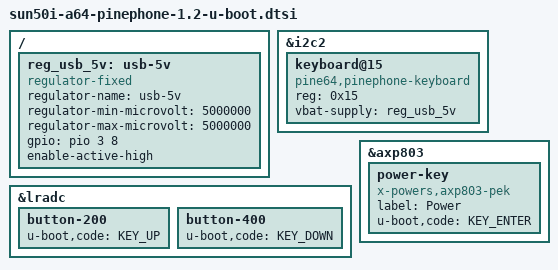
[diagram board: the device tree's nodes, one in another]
// SPDX-License-Identifier: (GPL-2.0+ OR MIT)
/*
 * U-Boot additions for the PinePhone: the three buttons act as a keyboard so
 * the boot menu can be driven without a serial console, and so does the
 * keyboard case when it is attached.
 *
 * `u-boot,code` is read in preference to `linux,code`, so the volume keys keep
 * their own meaning under Linux.
 */

#include "sunxi-u-boot.dtsi"
#include <dt-bindings/gpio/gpio.h>
#include <dt-bindings/input/input.h>

/ {
	/* The 5V boost the keyboard case's MCU runs from, as the kernel's own tree describes it. */
	reg_usb_5v: usb-5v {
		compatible = "regulator-fixed";
		regulator-name = "usb-5v";
		regulator-min-microvolt = <5000000>;
		regulator-max-microvolt = <5000000>;
		gpio = <&pio 3 8 GPIO_ACTIVE_HIGH>; /* PD8 */
		enable-active-high;
	};
};

&i2c2 {
	keyboard@15 {
		compatible = "pine64,pinephone-keyboard";
		reg = <0x15>;
		vbat-supply = <&reg_usb_5v>;
	};
};

&lradc {
	button-200 {
		u-boot,code = <KEY_UP>;
	};

	button-400 {
		u-boot,code = <KEY_DOWN>;
	};
};

&axp803 {
	power-key {
		compatible = "x-powers,axp803-pek";
		label = "Power";
		u-boot,code = <KEY_ENTER>;
	};
};
